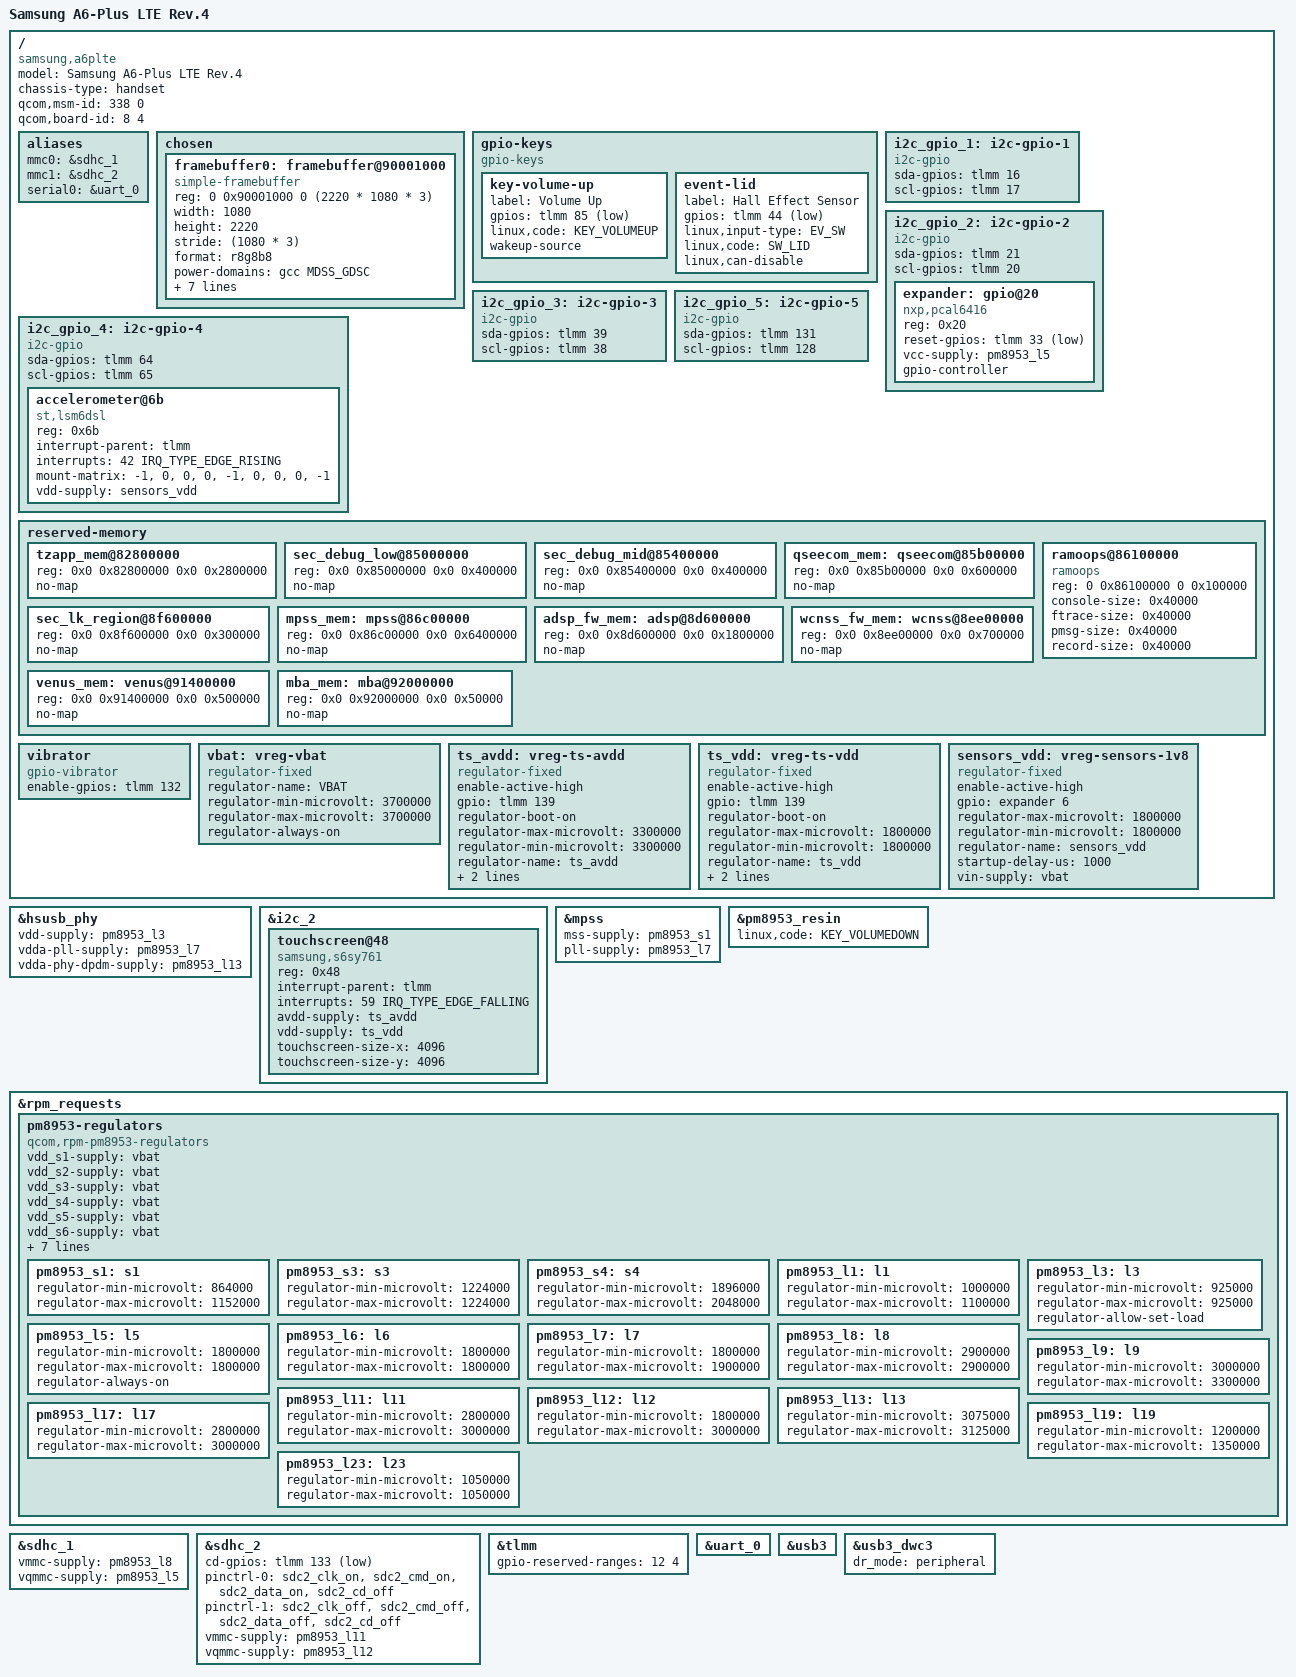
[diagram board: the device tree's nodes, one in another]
// SPDX-License-Identifier: BSD-3-Clause
// Copyright (c) 2022, The Linux Foundation. All rights reserved.

/dts-v1/;

#include "msm8953.dtsi"
#include "pm8953.dtsi"

/delete-node/ &wcnss_fw_mem;

/ {
	model = "Samsung A6-Plus LTE Rev.4";
	compatible = "samsung,a6plte", "qcom,sdm450";
	chassis-type = "handset";
	qcom,msm-id = <338 0>;
	qcom,board-id = <8 4>;

	aliases {
		mmc0 = &sdhc_1;
		mmc1 = &sdhc_2;
		serial0 = &uart_0;
	};

	chosen {
		#address-cells = <2>;
		#size-cells = <2>;
		ranges;

		framebuffer0: framebuffer@90001000 {
			compatible = "simple-framebuffer";
			reg = <0 0x90001000 0 (2220 * 1080 * 3)>;

			width = <1080>;
			height = <2220>;
			stride = <(1080 * 3)>;
			format = "r8g8b8";

			power-domains = <&gcc MDSS_GDSC>;

			clocks = <&gcc GCC_MDSS_AHB_CLK>,
				 <&gcc GCC_MDSS_AXI_CLK>,
				 <&gcc GCC_MDSS_VSYNC_CLK>,
				 <&gcc GCC_MDSS_MDP_CLK>,
				 <&gcc GCC_MDSS_BYTE0_CLK>,
				 <&gcc GCC_MDSS_PCLK0_CLK>,
				 <&gcc GCC_MDSS_ESC0_CLK>;
		};
	};

	gpio-keys {
		compatible = "gpio-keys";

		key-volume-up {
			label = "Volume Up";
			gpios = <&tlmm 85 GPIO_ACTIVE_LOW>;
			linux,code = <KEY_VOLUMEUP>;
			wakeup-source;
		};

		event-lid {
			label = "Hall Effect Sensor";
			gpios = <&tlmm 44 GPIO_ACTIVE_LOW>;
			linux,input-type = <EV_SW>;
			linux,code = <SW_LID>;
			linux,can-disable;
		};
	};

	i2c_gpio_1: i2c-gpio-1 {
		compatible = "i2c-gpio";
		sda-gpios = <&tlmm 16 (GPIO_ACTIVE_HIGH|GPIO_OPEN_DRAIN)>;
		scl-gpios = <&tlmm 17 (GPIO_ACTIVE_HIGH|GPIO_OPEN_DRAIN)>;

		#address-cells = <1>;
		#size-cells = <0>;
	};

	i2c_gpio_2: i2c-gpio-2 {
		compatible = "i2c-gpio";
		sda-gpios = <&tlmm 21 (GPIO_ACTIVE_HIGH|GPIO_OPEN_DRAIN)>;
		scl-gpios = <&tlmm 20 (GPIO_ACTIVE_HIGH|GPIO_OPEN_DRAIN)>;

		#address-cells = <1>;
		#size-cells = <0>;
	};

	i2c_gpio_3: i2c-gpio-3 {
		compatible = "i2c-gpio";
		sda-gpios = <&tlmm 39 (GPIO_ACTIVE_HIGH|GPIO_OPEN_DRAIN)>;
		scl-gpios = <&tlmm 38 (GPIO_ACTIVE_HIGH|GPIO_OPEN_DRAIN)>;

		#address-cells = <1>;
		#size-cells = <0>;
	};

	i2c_gpio_4: i2c-gpio-4 {
		compatible = "i2c-gpio";
		sda-gpios = <&tlmm 64 (GPIO_ACTIVE_HIGH|GPIO_OPEN_DRAIN)>;
		scl-gpios = <&tlmm 65 (GPIO_ACTIVE_HIGH|GPIO_OPEN_DRAIN)>;

		#address-cells = <1>;
		#size-cells = <0>;
	};

	i2c_gpio_5: i2c-gpio-5 {
		compatible = "i2c-gpio";
		sda-gpios = <&tlmm 131 (GPIO_ACTIVE_HIGH|GPIO_OPEN_DRAIN)>;
		scl-gpios = <&tlmm 128 (GPIO_ACTIVE_HIGH|GPIO_OPEN_DRAIN)>;

		#address-cells = <1>;
		#size-cells = <0>;
	};

	reserved-memory {
		tzapp_mem@82800000 {
			reg = <0x0 0x82800000 0x0 0x2800000>;
			no-map;
		};

		sec_debug_low@85000000 {
			reg = <0x0 0x85000000 0x0 0x400000>;
			no-map;
		};

		/* This region and sec_lk_region are optional and
		 * might be removed by bootloader depending on its
		 * debugging settings.
		 */
		sec_debug_mid@85400000 {
			reg = <0x0 0x85400000 0x0 0x400000>;
			no-map;
		};

		qseecom_mem: qseecom@85b00000 {
			reg = <0x0 0x85b00000 0x0 0x600000>;
			no-map;
		};

		sec_lk_region@8f600000 {
			reg = <0x0 0x8f600000 0x0 0x300000>;
			no-map;
		};

		ramoops@86100000 {
			compatible = "ramoops";
			reg = <0 0x86100000 0 0x100000>;

			console-size = <0x40000>;
			ftrace-size = <0x40000>;
			pmsg-size = <0x40000>;
			record-size = <0x40000>;
		};

		mpss_mem: mpss@86c00000 {
			reg = <0x0 0x86c00000 0x0 0x6400000>;
			no-map;
		};

		adsp_fw_mem: adsp@8d600000  {
			reg = <0x0 0x8d600000 0x0 0x1800000>;
			no-map;
		};

		wcnss_fw_mem: wcnss@8ee00000 {
			reg = <0x0 0x8ee00000 0x0 0x700000>;
			no-map;
		};

		venus_mem: venus@91400000 {
			reg = <0x0 0x91400000 0x0 0x500000>;
			no-map;
		};

		mba_mem: mba@92000000 {
			reg = <0x0 0x92000000 0x0 0x50000>;
			no-map;
		};
	};

	vibrator {
		compatible = "gpio-vibrator";

		enable-gpios = <&tlmm 132 GPIO_ACTIVE_HIGH>;
	};

	vbat: vreg-vbat {
		compatible = "regulator-fixed";
		regulator-name = "VBAT";

		regulator-min-microvolt = <3700000>;
		regulator-max-microvolt = <3700000>;
		regulator-always-on;
	};

	ts_avdd: vreg-ts-avdd {
		compatible = "regulator-fixed";

		enable-active-high;
		gpio = <&tlmm 139 GPIO_ACTIVE_HIGH>;
		regulator-boot-on;
		regulator-max-microvolt = <3300000>;
		regulator-min-microvolt = <3300000>;
		regulator-name = "ts_avdd";
		startup-delay-us = <1000>;
		vin-supply = <&vbat>;
	};

	ts_vdd: vreg-ts-vdd {
		compatible = "regulator-fixed";

		enable-active-high;
		gpio = <&tlmm 139 GPIO_ACTIVE_HIGH>;
		regulator-boot-on;
		regulator-max-microvolt = <1800000>;
		regulator-min-microvolt = <1800000>;
		regulator-name = "ts_vdd";
		startup-delay-us = <1000>;
		vin-supply = <&pm8953_s4>;
	};

	sensors_vdd: vreg-sensors-1v8 {
		compatible = "regulator-fixed";

		enable-active-high;
		gpio = <&expander 6 GPIO_ACTIVE_HIGH>;
		regulator-max-microvolt = <1800000>;
		regulator-min-microvolt = <1800000>;
		regulator-name = "sensors_vdd";
		startup-delay-us = <1000>;
		vin-supply = <&vbat>;
	};
};

&hsusb_phy {
	status = "okay";

	vdd-supply = <&pm8953_l3>;
	vdda-pll-supply = <&pm8953_l7>;
	vdda-phy-dpdm-supply = <&pm8953_l13>;
};

&i2c_2 {
	status = "okay";

	touchscreen@48 {
		compatible = "samsung,s6sy761";
		reg = <0x48>;

		interrupt-parent = <&tlmm>;
		interrupts = <59 IRQ_TYPE_EDGE_FALLING>;

		avdd-supply = <&ts_avdd>;
		vdd-supply = <&ts_vdd>;

		touchscreen-size-x = <4096>;
		touchscreen-size-y = <4096>;
	};
};

&i2c_gpio_2 {
	expander: gpio@20 {
		compatible = "nxp,pcal6416";
		reg = <0x20>;

		reset-gpios = <&tlmm 33 GPIO_ACTIVE_LOW>;
		vcc-supply = <&pm8953_l5>;

		gpio-controller;
		#gpio-cells = <2>;
	};
};

&i2c_gpio_4 {
	accelerometer@6b {
		compatible = "st,lsm6dsl";
		reg = <0x6b>;

		interrupt-parent = <&tlmm>;
		interrupts = <42 IRQ_TYPE_EDGE_RISING>;
		mount-matrix = "-1",  "0",  "0",
			        "0", "-1",  "0",
			        "0",  "0", "-1";

		vdd-supply = <&sensors_vdd>;
	};
};

&mpss {
	status = "okay";

	mss-supply = <&pm8953_s1>;
	pll-supply = <&pm8953_l7>;
};

&pm8953_resin {
	status = "okay";
	linux,code = <KEY_VOLUMEDOWN>;
};

&rpm_requests {
	pm8953-regulators {
		compatible = "qcom,rpm-pm8953-regulators";

		vdd_s1-supply = <&vbat>;
		vdd_s2-supply = <&vbat>;
		vdd_s3-supply = <&vbat>;
		vdd_s4-supply = <&vbat>;
		vdd_s5-supply = <&vbat>;
		vdd_s6-supply = <&vbat>;
		vdd_s7-supply = <&vbat>;
		vdd_l1-supply = <&pm8953_s3>;
		vdd_l2_l3-supply = <&pm8953_s3>;
		vdd_l4_l5_l6_l7_l16_l19-supply = <&pm8953_s4>;
		vdd_l8_l11_l12_l13_l14_l15-supply = <&vbat>;
		vdd_l9_l10_l17_l18_l22-supply = <&vbat>;
		vdd_l23-supply = <&pm8953_s3>;

		pm8953_s1: s1 {
			regulator-min-microvolt = <864000>;
			regulator-max-microvolt = <1152000>;
		};

		pm8953_s3: s3 {
			regulator-min-microvolt = <1224000>;
			regulator-max-microvolt = <1224000>;
		};

		pm8953_s4: s4 {
			regulator-min-microvolt = <1896000>;
			regulator-max-microvolt = <2048000>;
		};

		pm8953_l1: l1 {
			regulator-min-microvolt = <1000000>;
			regulator-max-microvolt = <1100000>;
		};

		pm8953_l3: l3 {
			regulator-min-microvolt = <925000>;
			regulator-max-microvolt = <925000>;
			regulator-allow-set-load;
		};

		pm8953_l5: l5 {
			regulator-min-microvolt = <1800000>;
			regulator-max-microvolt = <1800000>;
			regulator-always-on;
		};

		pm8953_l6: l6 {
			regulator-min-microvolt = <1800000>;
			regulator-max-microvolt = <1800000>;
		};

		pm8953_l7: l7 {
			regulator-min-microvolt = <1800000>;
			regulator-max-microvolt = <1900000>;
		};

		pm8953_l8: l8 {
			regulator-min-microvolt = <2900000>;
			regulator-max-microvolt = <2900000>;
		};

		pm8953_l9: l9 {
			regulator-min-microvolt = <3000000>;
			regulator-max-microvolt = <3300000>;
		};

		pm8953_l11: l11 {
			regulator-min-microvolt = <2800000>;
			regulator-max-microvolt = <3000000>;
		};

		pm8953_l12: l12 {
			regulator-min-microvolt = <1800000>;
			regulator-max-microvolt = <3000000>;
		};

		pm8953_l13: l13 {
			regulator-min-microvolt = <3075000>;
			regulator-max-microvolt = <3125000>;
		};

		pm8953_l17: l17 {
			regulator-min-microvolt = <2800000>;
			regulator-max-microvolt = <3000000>;
		};

		pm8953_l19: l19 {
			regulator-min-microvolt = <1200000>;
			regulator-max-microvolt = <1350000>;
		};

		pm8953_l23: l23 {
			regulator-min-microvolt = <1050000>;
			regulator-max-microvolt = <1050000>;
		};
	};
};

&sdhc_1 {
	status = "okay";

	vmmc-supply = <&pm8953_l8>;
	vqmmc-supply = <&pm8953_l5>;
};

&sdhc_2 {
	status = "okay";

	cd-gpios = <&tlmm 133 GPIO_ACTIVE_LOW>;

	pinctrl-names = "default", "sleep";
	pinctrl-0 = <&sdc2_clk_on &sdc2_cmd_on &sdc2_data_on &sdc2_cd_off>;
	pinctrl-1 = <&sdc2_clk_off &sdc2_cmd_off &sdc2_data_off &sdc2_cd_off>;

	vmmc-supply = <&pm8953_l11>;
	vqmmc-supply = <&pm8953_l12>;
};

&tlmm {
	/* Fingerprint sensor at SPI4 (BLSP1 QUP4) */
	gpio-reserved-ranges = <12 4>;
};

&uart_0 {
	status = "okay";
};

&usb3 {
	status = "okay";
};

&usb3_dwc3 {
	dr_mode = "peripheral";
};
